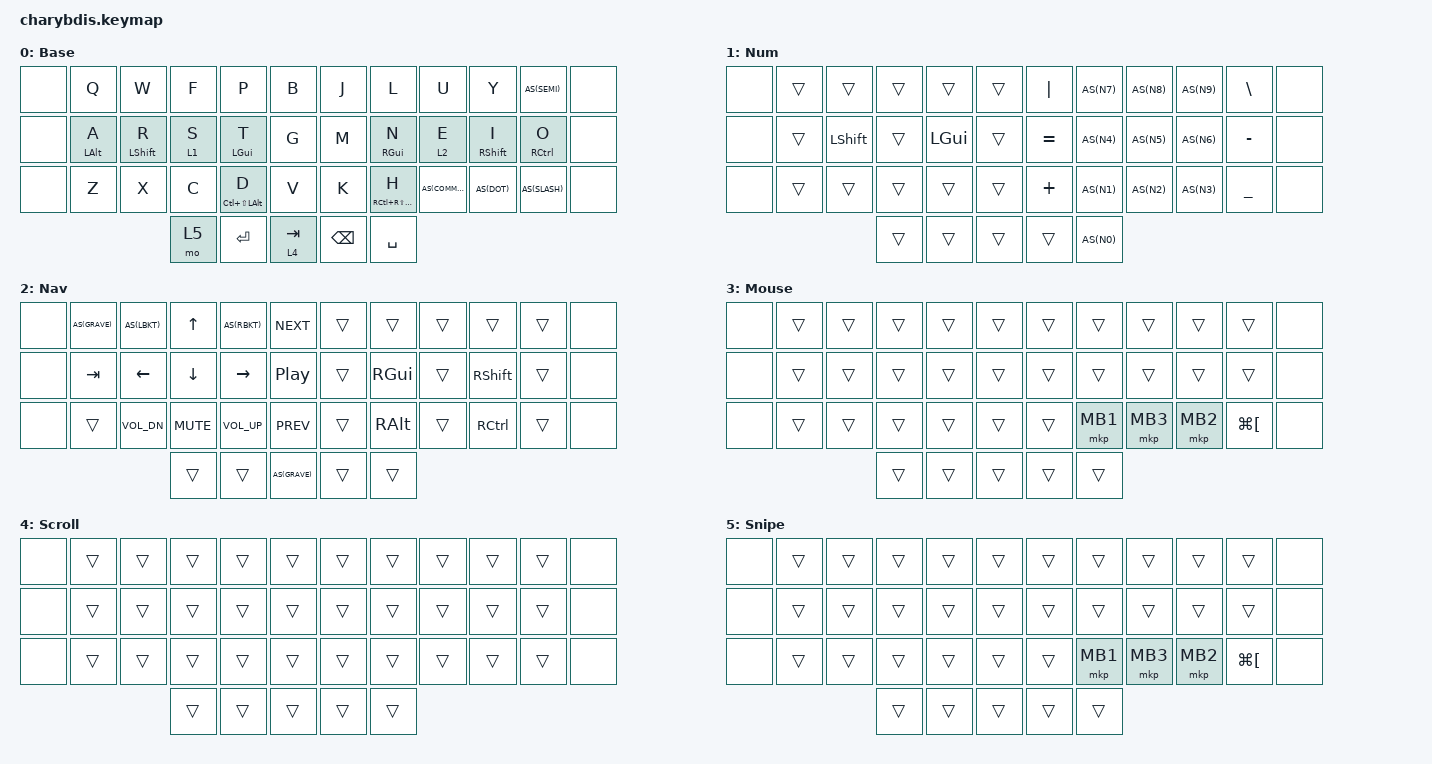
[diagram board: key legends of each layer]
#include <behaviors.dtsi>
#include <dt-bindings/zmk/keys.h>
#include <dt-bindings/zmk/pointing.h>

#define BASE 0
#define NUM 1
#define NAV 2
#define MOUSE 3
#define SCROLL 4
#define SNIPE 5

#define KEYS_L 0 1 2 3 4 10 11 12 13 14 20 21 22 23 24
#define KEYS_R 5 6 7 8 9 15 16 17 18 19 25 26 27 28 29
#define THUMBS 30 31 32 33 34 35
#define AS(keycode) &as LS(keycode) keycode     // Autoshift Macro

/* --- KEYMAP CONFIG --- */
// ╭──────┬──────┬──────┬──────┬──────┬──────╮  ╭──────┬──────┬──────┬──────┬──────┬──────╮
//    00     01     02     03    04      05        06     07     08     09     10     11
// ├──────┼──────┼──────┼──────┼──────┼──────┤  ├──────┼──────┼──────┼──────┼──────┼──────┤
//    12     13     14     15    16      17        18     19     20     21     22     23
// ├──────┼──────┼──────┼──────┼──────┼──────┤  ├──────┼──────┼──────┼──────┼──────┼──────┤
//    24     25     26     27    28      29        30     31     32     33     34     35
// ╰──────┴──────┴──────┼──────┼──────┼──────┤  ├──────┼──────┼──────┴──────┴──────┴──────╯
//                         36     37     38        39     40
//                      ╰──────┴──────┴──────╯  ╰──────┴──────╯


&sk {
  release-after-ms = <600>;
  quick-release;
};

&mt {
  flavor = "balanced";
  quick-tap-ms = <150>;
  require-prior-idle-ms = <80>;   // HUGE improvement
  tapping-term-ms = <200>;        // Add this line
};

/ {
  behaviors {
    skcaps: sticky_keys_double_tap_caps {
      compatible = "zmk,behavior-tap-dance";
      #binding-cells = <0>;
      tapping-term-ms = <250>;
      bindings = <&sk LSFT>, <&kp CAPSLOCK>; // tap, double_tap
    };

    as: auto_shift {
      compatible = "zmk,behavior-hold-tap";
      #binding-cells = <2>;
      tapping-term-ms = <150>;
      quick-tap-ms = <0>;
      flavor = "tap-preferred";
      bindings = <&kp>, <&kp>;
    };
  };

  macros {
    meh: meh {
      compatible = "zmk,behavior-macro";
      #binding-cells = <0>;
      bindings = <&macro_press &kp LCTRL &kp LALT &kp LSHFT
                  &macro_pause_for_release
                  &macro_release &kp LCTRL &kp LALT &kp LSHFT>;
    };

    esc_base: esc_base {
      compatible = "zmk,behavior-macro";
      #binding-cells = <0>;
      bindings = <&kp ESC>, <&to 0>;
    };
  };

  combos {
    compatible = "zmk,combos";
    timeout-ms = <20>;
    require-prior-idle-ms = <250>;

    combo_lesc {
        key-positions = <2 3 4>;
        bindings = <&esc_base>;
    };

    combo_resc {
        key-positions = <7 8 9>;
        bindings = <&esc_base>;
    };

    combo_quote {
        key-positions = <8 9>;
        bindings = <&as LS(SINGLE_QUOTE) SINGLE_QUOTE>;
    };

    combo_tilde {
        key-positions = <2 3>;
        bindings = <&as LS(GRAVE) GRAVE>;
    };

    combo_sticky_shift {
        key-positions = <14 21>;
        timeout-ms = <75>;
        bindings = <&skcaps>;
    };

    combo_scroll {
        bindings = <&mo 4>;
        key-positions = <32 33>;
    };

    combo_snipe {
        bindings = <&mo 5>;
        key-positions = <25 26>;
    };

    combo_meh {
        key-positions = <31 32>;
        bindings = <&meh>;
    };
  };

  chosen {
    zmk,physical-layout = &charybdis_6col_layout;
  };

  keymap {
    compatible = "zmk,keymap";

    Base {
      display-name = "Base";
      bindings = <
        &none &kp Q         &kp W         &kp F         &kp P            &kp B            &kp J          &kp L             &kp U         &kp Y            AS(SEMI)    &none
        &none &mt LALT A   &mt LSHFT R   &lt 1 S      &mt LGUI T       &kp G            &kp M          &mt RGUI N        &lt 2 E       &mt RSHFT I      &mt RCTRL O &none
        &none &kp Z         &kp X         &kp C         &mt LC(LS(LALT)) D       &kp V            &kp K          &mt RC(RS(RALT)) H         AS(COMMA)     AS(DOT)          AS(SLASH)   &none
                                          &mo 5         &kp ENTER        &lt 4 TAB    &kp BACKSPACE  &kp SPACE
      >;
    };

    Num {
      display-name = "Num";
      bindings = <
        &none &trans   &trans     &trans   &trans    &trans          &kp PIPE   AS(N7)  AS(N8)  AS(N9)  &kp BSLH       &none
        &none &trans   &kp LSHFT  &trans   &kp LGUI  &trans          &kp EQUAL  AS(N4)  AS(N5)  AS(N6)  &kp MINUS      &none
        &none &trans   &trans     &trans   &trans    &trans          &kp PLUS   AS(N1)  AS(N2)  AS(N3)  &kp UNDERSCORE &none
                                  &trans   &trans    &trans          &trans     AS(N0)
      >;
    };

    Nav {
      display-name = "Nav";
      bindings = <
        &none AS(GRAVE)  AS(LBKT)      &kp UP      AS(RBKT)     &kp C_NEXT     &trans   &trans   &trans &trans    &trans &none
        &none &kp TAB    &kp LEFT      &kp DOWN    &kp RIGHT    &kp C_PP       &trans   &kp RGUI &trans &kp RSHFT &trans &none
        &none &trans     &kp C_VOL_DN  &kp C_MUTE  &kp C_VOL_UP &kp C_PREV     &trans   &kp RALT &trans &kp RCTRL &trans &none
                                        &trans      &trans      AS(GRAVE)      &trans   &trans
        >;
    };

    Mouse {
      display-name = "Mouse";
      bindings = <
        &none &trans    &trans    &trans    &trans    &trans    &trans    &trans    &trans    &trans    &trans        &none
        &none &trans    &trans    &trans    &trans    &trans    &trans    &trans    &trans    &trans    &trans        &none
        &none &trans    &trans    &trans    &trans    &trans    &trans    &mkp MB1  &mkp MB3  &mkp MB2  &kp LG(LBKT)  &none
                            &trans    &trans    &trans    &trans    &trans
      >;
    };

    Scroll {
      display-name = "Scroll";
      bindings = <
        &none &trans    &trans    &trans    &trans    &trans    &trans    &trans    &trans    &trans    &trans &none
        &none &trans    &trans    &trans    &trans    &trans    &trans    &trans    &trans    &trans    &trans &none
        &none &trans    &trans    &trans    &trans    &trans    &trans    &trans    &trans    &trans    &trans &none
                                  &trans    &trans    &trans    &trans    &trans

      >;
    };

    Snipe {
      display-name = "Snipe";
      bindings = <
        &none &trans    &trans    &trans    &trans    &trans    &trans    &trans    &trans    &trans    &trans &none
        &none &trans    &trans    &trans    &trans    &trans    &trans    &trans    &trans    &trans    &trans &none
        &none &trans    &trans    &trans    &trans    &trans    &trans    &mkp MB1  &mkp MB3  &mkp MB2  &kp LG(LBKT)  &none
                                  &trans    &trans    &trans    &trans    &trans
      >;
    };
  };
};
